# BAT32A237 register map
Vendor: CMS; Series: BAT32A237; File version: 1.2
CPU: CM0+ r0p1, little endian, MPU, no FPU, VTOR, 2 interrupt priority bits
Registers are 8-bit, read-write, reset 0x0 unless marked. A register's access mark holds for its fields unless they carry their own. Offsets are from the block's base; [hi:lo] are bit positions; {n}, {i} and the like mark numbered series.

## FMC — Flash Memory Controller
Base 0x40020000
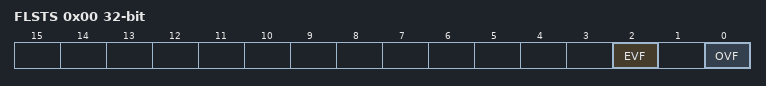
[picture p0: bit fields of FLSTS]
0x00 FLSTS 32-bit — Flash status register
  [2] EVF — Flash hardware verification error flag
  [0] OVF — Flash erase or write operaiton finish
0x04 FLOPMD1 32-bit (reset mask 0xFF) — Flash operation mode register 1
0x08 FLOPMD2 32-bit (reset mask 0xFF) — Flash operation mode register 2
0x0C FLERMD 32-bit (reset mask 0x18) — Flash erase mode register
0x10 FLCERCNT 32-bit (reset mask 0x800001FF) — Flash chip erase control register
0x14 FLSERCNT 32-bit (reset mask 0x800001FF) — Flash sector erase control register
0x1C FLPROCNT 32-bit (reset mask 0x81FF81FF) — Flash program (write) control register
0x20 FLPROT 32-bit (reset mask 0xFF) — Flash protect control register

## SAF — Flash memory CRC operation function (High-Speed CRC)
Base 0x40020100
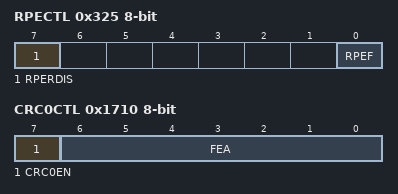
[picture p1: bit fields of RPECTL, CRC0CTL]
0x325 RPECTL — RAM parity error control register
  [7] RPERDIS — Disable RAM parity error reset
    0=Enable parity error reset; 1=Disable parity error reset
  [0] RPEF — Parity error status flag
    0=NoError (No parity error has occurred); 1=Error (Parity error has occurred)
0x1710 CRC0CTL — Flash memory CRC control register
  [7] CRC0EN — Control of high-speed CRC operation
  [6:0] FEA — High-speed CRC operation range
0x1712 PGCRCL 16-bit — Flash memory CRC operation result register
0x20378 SFRGD 16-bit (reset mask 0xF) — SFR guard control register
0x231FA CRCD 16-bit (reset mask 0xFF) — CRC data register
0x232AC CRCIN — CRC input register

## CRC — General Purpose CRC
Base 0x400432F0
0x0A CRCD 16-bit (reset mask 0xFF) — CRC data register
0xBC CRCIN — CRC input register

## DBG — DBG Controller
Base 0x4001B000
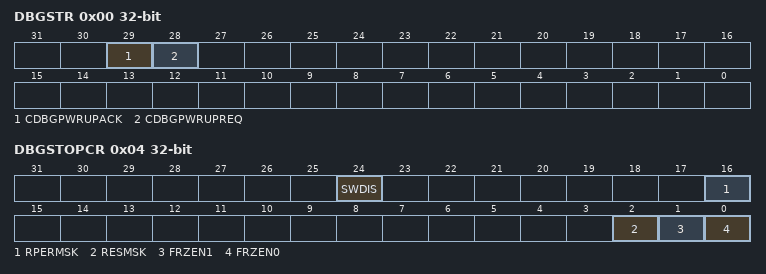
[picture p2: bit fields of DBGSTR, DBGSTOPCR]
0x00 DBGSTR 32-bit ro — Debug status register
  [29] CDBGPWRUPACK — DBG Power Up Acknowledgement
  [28] CDBGPWRUPREQ — DBG Power Up Request
0x04 DBGSTOPCR 32-bit — Debug Stop Control register
  [24] SWDIS — SWD Disable
  [16] RPERMSK — Mask RAM parity error in debug mode
  [2] RESMSK — Mask internal reset in debug mode
  [1] FRZEN1 — Stop Communation family macros when cpu halted
  [0] FRZEN0 — Stop Timer family macros when cpu halted

## CAN0 — CAN0 Controller
Base 0x40045400
0x00 CGMCTRL 16-bit — CAN global module control register
0x02 CGMCS (reset mask 0xF) — CAN global module clock select register
0x06 CGMABT 16-bit — CAN global automatic block transmission control register
0x08 CGMABTD (reset mask 0xF) — CAN global automatic block transmission delay setting register
0x40 CMASK1{x} (x=L,H; step 0x2) 16-bit — CAN module mask 1 register
0x44 CMASK2{x} (x=L,H; step 0x2) 16-bit — CAN module mask 2 register
0x48 CMASK3{x} (x=L,H; step 0x2) 16-bit — CAN module mask 3 register
0x4C CMASK4{x} (x=L,H; step 0x2) 16-bit — CAN module mask 4 register
0x50 CCTRL 16-bit — CAN module control register
0x52 CLEC — CAN module last error code register
0x53 CINFO ro — CAN module information register
0x54 CERC 16-bit ro — CAN module error counter register
0x56 CIE 16-bit — CAN module interrupt enable register
0x58 CINTS 16-bit — CAN module interrupt status register
0x5A CBRP — CAN module bit rate prescaler register
0x5C CBTR 16-bit — CAN module bit rate register
0x5E CLIPT ro — CAN module last in-pointer register
0x60 CRGPT 16-bit — CAN module receive history list register
0x62 CLOPT ro — CAN module last out-pointer register
0x64 CTGPT 16-bit — CAN module transmit history list register
0x66 CTS 16-bit — CAN module time stamp register

## CAN0MSG00 — CAN0 Controller Message 00
Base 0x40045500
Same registers: CAN0MSG{n:02} {0x40045500+0x10*n} (n=1..15)
0x00 CMDB{x} (x=01,23,45,67; step 0x2) 16-bit — CAN message data byte {x} register
{0x0+i} CMDB{i} (i=0..1) (alternate view of CMDB01) — CAN message data byte {i} register
{0x0+i} CMDB{i} (i=2..3) (alternate view of CMDB23) — CAN message data byte {i} register
{0x0+i} CMDB{i} (i=4..5) (alternate view of CMDB45) — CAN message data byte {i} register
{0x0+i} CMDB{i} (i=6..7) (alternate view of CMDB67) — CAN message data byte {i} register
0x08 CMDLC — CAN message data length register
0x09 CMCONF — CAN message configuration register
0x0A CMIDL 16-bit — CAN message ID register
0x0C CMIDH 16-bit — CAN message ID register
0x0E CMCTRL 16-bit — CAN message control register

## BGR — Temperature Sensor calibration data
Base 0x00500660
0x00 VBG125 16-bit ro — The A/D conversion value of VBGR at 85 degrees and 3.0V reference voltage
0x04 VBG25 16-bit ro — The A/D conversion value of VBGR at 25 degrees and 3.0V reference voltage

## TSN — Temperature Sensor calibration data
Base 0x00500668
0x00 TSN125 16-bit ro — The A/D conversion value of Temperature Sensor at 85 degrees and 3.0V reference voltage
0x04 TSN25 16-bit ro — The A/D conversion value of Temperature Sensor at 25 degrees and 3.0V reference voltage

## UID — 128-bit Unique ID
Base 0x0050084C
{0x0+4i} UID{i} (i=0..3) 32-bit ro — UID word {i}
